# ATSAMA5D27 register map
Vendor: Microchip Technology Inc.; File version: 1.0
CPU: CA5 r0p1, little endian, no MPU, no FPU, 4 interrupt priority bits
Address unit: 32 bits
Registers are 32-bit, read-write, reset 0x0 unless marked. A register's access mark holds for its fields unless they carry their own. Offsets are from the block's base; [hi:lo] are bit positions; {n}, {i} and the like mark numbered series; 'fields as' and 'values as' point back to an identical list.

## PWM — Pulse Width Modulation Controller
Base 0xF802C000
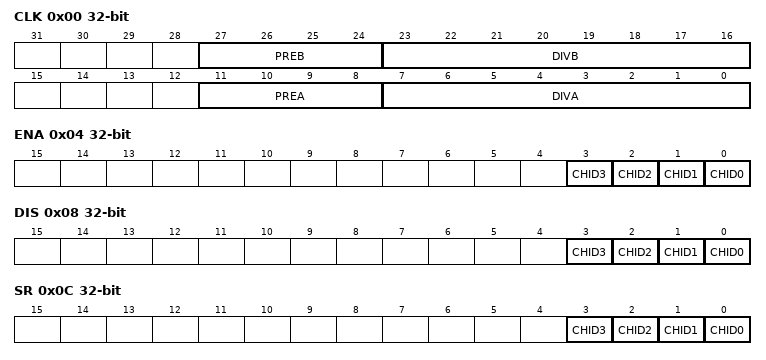
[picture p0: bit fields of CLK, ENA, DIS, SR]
0x00 CLK — PWM Clock Register
  [27:24] PREB — CLKB Source Clock Selection
    0=CLK (Peripheral clock); 1=CLK_DIV2 (Peripheral clock/2); 2=CLK_DIV4 (Peripheral clock/4); 3=CLK_DIV8 (Peripheral clock/8); 4=CLK_DIV16 (Peripheral clock/16); 5=CLK_DIV32 (Peripheral clock/32); 6=CLK_DIV64 (Peripheral clock/64); 7=CLK_DIV128 (Peripheral clock/128); 8=CLK_DIV256 (Peripheral clock/256); 9=CLK_DIV512 (Peripheral clock/512); 10=CLK_DIV1024 (Peripheral clock/1024)
  [23:16] DIVB — CLKB Divide Factor
    0=CLKB_POFF (CLKB clock is turned off); 1=PREB (CLKB clock is clock selected by PREB)
  [11:8] PREA — CLKA Source Clock Selection
    values as PREB
  [7:0] DIVA — CLKA Divide Factor
    0=CLKA_POFF (CLKA clock is turned off); 1=PREA (CLKA clock is clock selected by PREA)
0x04 ENA wo — PWM Enable Register
  [n] CHID{n} rw (n=0..3) — Channel ID
0x08 DIS wo — PWM Disable Register
  [n] CHID{n} rw (n=0..3) — Channel ID
0x0C SR ro — PWM Status Register
  [n] CHID{n} rw (n=0..3) — Channel ID
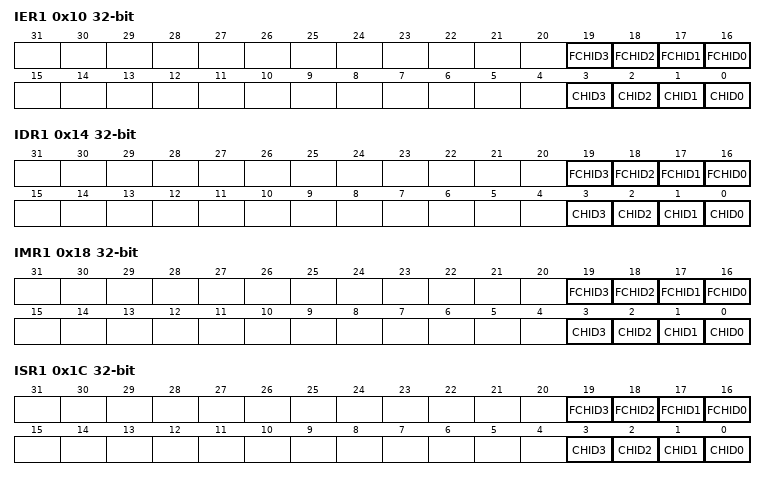
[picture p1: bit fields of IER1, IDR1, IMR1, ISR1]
0x10 IER1 wo — PWM Interrupt Enable Register 1
  [n+16] FCHID{n} rw (n=0..3) — Fault Protection Trigger on Channel {n} Interrupt Enable
  [n] CHID{n} rw (n=0..3) — Counter Event on Channel {n} Interrupt Enable
0x14 IDR1 wo — PWM Interrupt Disable Register 1
  [n+16] FCHID{n} rw (n=0..3) — Fault Protection Trigger on Channel {n} Interrupt Disable
  [n] CHID{n} rw (n=0..3) — Counter Event on Channel {n} Interrupt Disable
0x18 IMR1 ro — PWM Interrupt Mask Register 1
  [n+16] FCHID{n} rw (n=0..3) — Fault Protection Trigger on Channel {n} Interrupt Mask
  [n] CHID{n} rw (n=0..3) — Counter Event on Channel {n} Interrupt Mask
0x1C ISR1 ro — PWM Interrupt Status Register 1
  [n+16] FCHID{n} rw (n=0..3) — Fault Protection Trigger on Channel {n}
  [n] CHID{n} rw (n=0..3) — Counter Event on Channel {n}
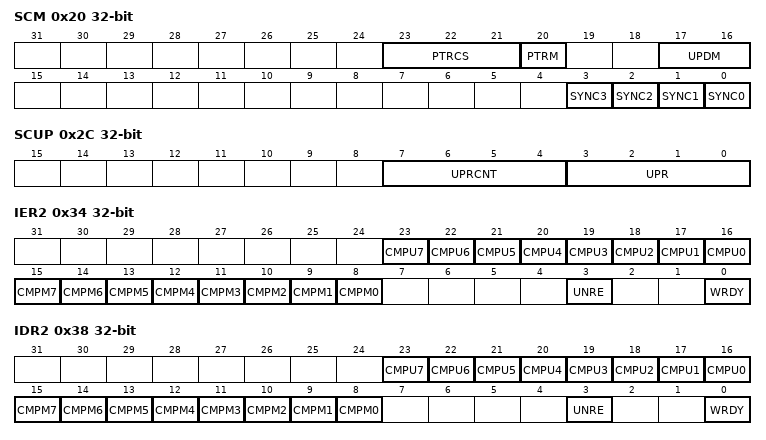
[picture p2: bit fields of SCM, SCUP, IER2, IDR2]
0x20 SCM — PWM Sync Channels Mode Register
  [23:21] PTRCS — DMA Controller Transfer Request Comparison Selection
  [20] PTRM — DMA Controller Transfer Request Mode
  [17:16] UPDM — Synchronous Channels Update Mode
    0=MODE0 (Manual write of double buffer registers and manual update of synchronous channels); 1=MODE1 (Manual write of double buffer registers and automatic update of synchronous channels); 2=MODE2 (Automatic write of duty-cycle update registers by the DMA Controller and automatic update of synchronous channels)
  [n] SYNC{n} (n=0..3) — Synchronous Channel {n}
0x24 DMAR wo — PWM DMA Register
  [23:0] DMADUTY rw — Duty-Cycle Holding Register for DMA Access
0x28 SCUC — PWM Sync Channels Update Control Register
  [0] UPDULOCK — Synchronous Channels Update Unlock
0x2C SCUP — PWM Sync Channels Update Period Register
  [7:4] UPRCNT — Update Period Counter
  [3:0] UPR — Update Period
0x30 SCUPUPD wo — PWM Sync Channels Update Period Update Register
  [3:0] UPRUPD rw — Update Period Update
0x34 IER2 wo — PWM Interrupt Enable Register 2
  [n+16] CMPU{n} rw (n=0..7) — Comparison {n} Update Interrupt Enable
  [n+8] CMPM{n} rw (n=0..7) — Comparison {n} Match Interrupt Enable
  [3] UNRE rw — Synchronous Channels Update Underrun Error Interrupt Enable
  [0] WRDY rw — Write Ready for Synchronous Channels Update Interrupt Enable
0x38 IDR2 wo — PWM Interrupt Disable Register 2
  [n+16] CMPU{n} rw (n=0..7) — Comparison {n} Update Interrupt Disable
  [n+8] CMPM{n} rw (n=0..7) — Comparison {n} Match Interrupt Disable
  [3] UNRE rw — Synchronous Channels Update Underrun Error Interrupt Disable
  [0] WRDY rw — Write Ready for Synchronous Channels Update Interrupt Disable
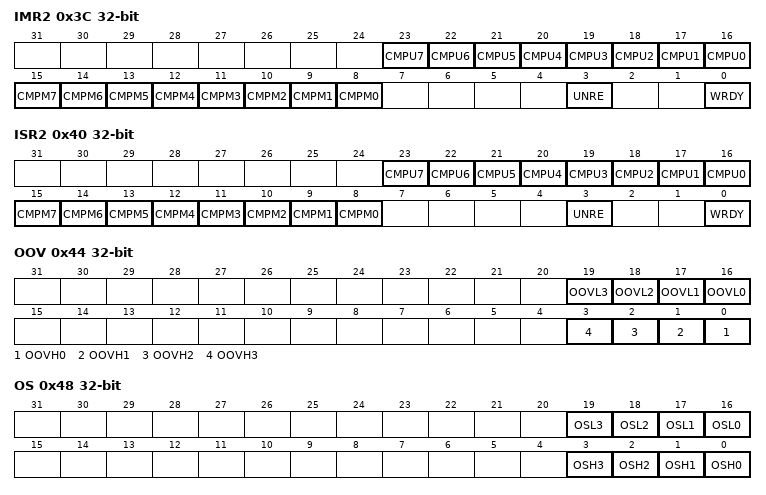
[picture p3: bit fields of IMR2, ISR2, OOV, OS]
0x3C IMR2 ro — PWM Interrupt Mask Register 2
  [n+16] CMPU{n} rw (n=0..7) — Comparison {n} Update Interrupt Mask
  [n+8] CMPM{n} rw (n=0..7) — Comparison {n} Match Interrupt Mask
  [3] UNRE rw — Synchronous Channels Update Underrun Error Interrupt Mask
  [0] WRDY rw — Write Ready for Synchronous Channels Update Interrupt Mask
0x40 ISR2 ro — PWM Interrupt Status Register 2
  [n+16] CMPU{n} rw (n=0..7) — Comparison {n} Update
  [n+8] CMPM{n} rw (n=0..7) — Comparison {n} Match
  [3] UNRE rw — Synchronous Channels Update Underrun Error
  [0] WRDY rw — Write Ready for Synchronous Channels Update
0x44 OOV — PWM Output Override Value Register
  [n+16] OOVL{n} (n=0..3) — Output Override Value for PWML output of the channel {n}
  [n] OOVH{n} (n=0..3) — Output Override Value for PWMH output of the channel {n}
0x48 OS — PWM Output Selection Register
  [n+16] OSL{n} (n=0..3) — Output Selection for PWML output of the channel {n}
  [n] OSH{n} (n=0..3) — Output Selection for PWMH output of the channel {n}
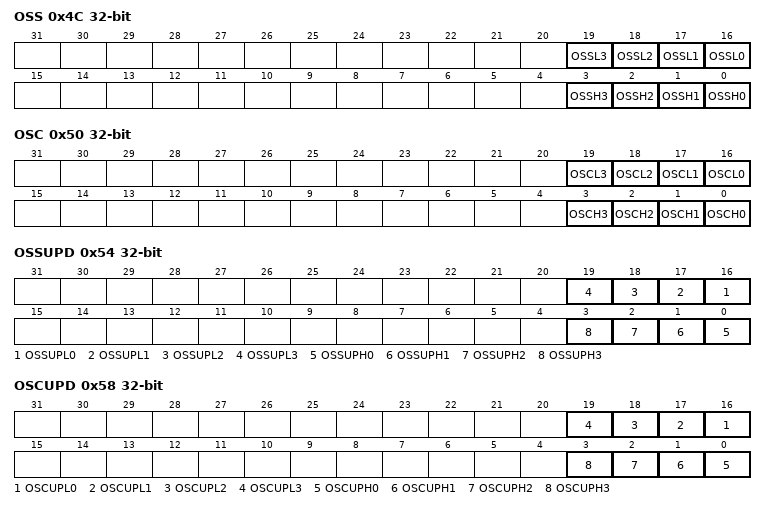
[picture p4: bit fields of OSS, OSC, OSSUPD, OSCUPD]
0x4C OSS wo — PWM Output Selection Set Register
  [n+16] OSSL{n} rw (n=0..3) — Output Selection Set for PWML output of the channel {n}
  [n] OSSH{n} rw (n=0..3) — Output Selection Set for PWMH output of the channel {n}
0x50 OSC wo — PWM Output Selection Clear Register
  [n+16] OSCL{n} rw (n=0..3) — Output Selection Clear for PWML output of the channel {n}
  [n] OSCH{n} rw (n=0..3) — Output Selection Clear for PWMH output of the channel {n}
0x54 OSSUPD wo — PWM Output Selection Set Update Register
  [n+16] OSSUPL{n} rw (n=0..3) — Output Selection Set for PWML output of the channel {n}
  [n] OSSUPH{n} rw (n=0..3) — Output Selection Set for PWMH output of the channel {n}
0x58 OSCUPD wo — PWM Output Selection Clear Update Register
  [n+16] OSCUPL{n} rw (n=0..3) — Output Selection Clear for PWML output of the channel {n}
  [n] OSCUPH{n} rw (n=0..3) — Output Selection Clear for PWMH output of the channel {n}
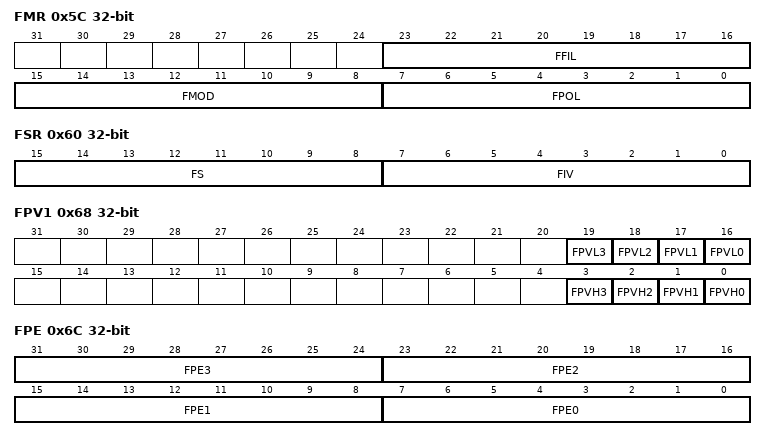
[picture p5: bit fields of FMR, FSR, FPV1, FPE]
0x5C FMR — PWM Fault Mode Register
  [23:16] FFIL — Fault Filtering
  [15:8] FMOD — Fault Activation Mode
  [7:0] FPOL — Fault Polarity
0x60 FSR ro — PWM Fault Status Register
  [15:8] FS rw — Fault Status
  [7:0] FIV rw — Fault Input Value
0x64 FCR wo — PWM Fault Clear Register
  [7:0] FCLR rw — Fault Clear
0x68 FPV1 — PWM Fault Protection Value Register 1
  [n+16] FPVL{n} (n=0..3) — Fault Protection Value for PWML output on channel {n}
  [n] FPVH{n} (n=0..3) — Fault Protection Value for PWMH output on channel {n}
0x6C FPE — PWM Fault Protection Enable Register
  [8n+7:8n] FPE{n} (n=0..3) — Fault Protection Enable for channel {n}
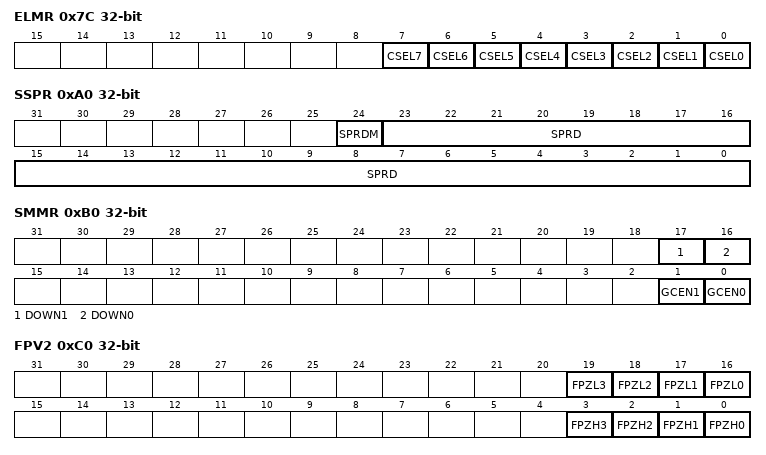
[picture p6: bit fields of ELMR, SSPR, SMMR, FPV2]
0x7C ELMR — PWM Event Line 0 Mode Register
  [n] CSEL{n} (n=0..7) — Comparison {n} Selection
0xA0 SSPR — PWM Spread Spectrum Register
  [24] SPRDM — Spread Spectrum Counter Mode
  [23:0] SPRD — Spread Spectrum Limit Value
0xA4 SSPUP wo — PWM Spread Spectrum Update Register
  [23:0] SPRDUP rw — Spread Spectrum Limit Value Update
0xB0 SMMR — PWM Stepper Motor Mode Register
  [17] DOWN1 — Down Count
  [16] DOWN0 — Down Count
  [1] GCEN1 — Gray Count Enable
  [0] GCEN0 — Gray Count Enable
0xC0 FPV2 — PWM Fault Protection Value 2 Register
  [n+16] FPZL{n} (n=0..3) — Fault Protection to Hi-Z for PWML output on channel {n}
  [n] FPZH{n} (n=0..3) — Fault Protection to Hi-Z for PWMH output on channel {n}
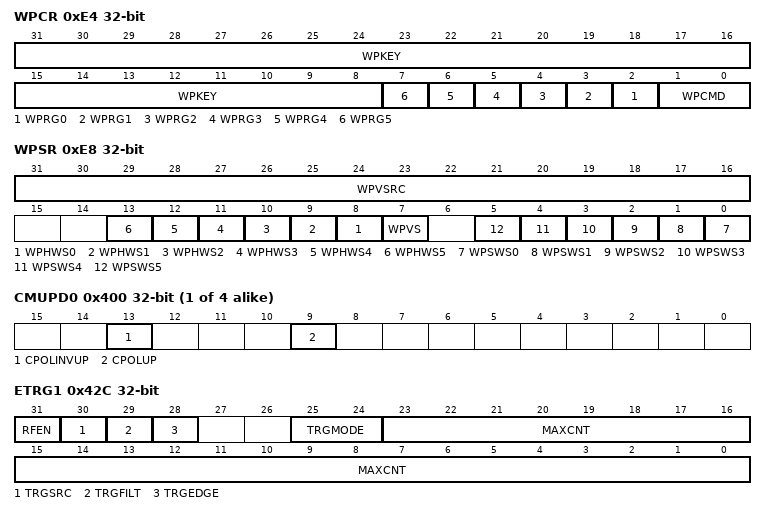
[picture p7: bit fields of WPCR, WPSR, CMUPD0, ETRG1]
0xE4 WPCR wo — PWM Write Protection Control Register
  [31:8] WPKEY rw — Write Protection Key
    0x50574D=PASSWD (Writing any other value in this field aborts the write operation of the WPCMD field.Always reads as 0)
  [n+2] WPRG{n} rw (n=0..5) — Write Protection Register Group {n}
  [1:0] WPCMD rw — Write Protection Command
    0=DISABLE_SW_PROT (Disables the software write protection of the register groups of which the bit WPRGx is at '1'.); 1=ENABLE_SW_PROT (Enables the software write protection of the register groups of which the bit WPRGx is at '1'.); 2=ENABLE_HW_PROT (Enables the hardware write protection of the register groups of which the bit WPRGx is at '1'. Only a hardware reset of the PWM controller can disable the hardware write protection. Moreover, to meet security requirements, the PIO lines associated with the PWM can not be configured through the PIO interface.)
0xE8 WPSR ro — PWM Write Protection Status Register
  [31:16] WPVSRC rw — Write Protect Violation Source
  [n+8] WPHWS{n} rw (n=0..5) — Write Protect HW Status
  [7] WPVS rw — Write Protect Violation Status
  [n] WPSWS{n} rw (n=0..5) — Write Protect SW Status
{0x400+0x20*i} CMUPD{i} wo (i=0..3) — PWM Channel Mode Update Register (ch_num = {i})
  [13] CPOLINVUP rw — Channel Polarity Inversion Update
  [9] CPOLUP rw — Channel Polarity Update
0x42C ETRG1 — PWM External Trigger Register 1
  [31] RFEN — Recoverable Fault Enable
  [30] TRGSRC — Trigger Source
  [29] TRGFILT — Filtered input
  [28] TRGEDGE — Edge Selection
    0=FALLING_ZERO (TRGMODE = 1: TRGINx event detection on falling edge.TRGMODE = 2, 3: TRGINx active level is 0); 1=RISING_ONE (TRGMODE = 1: TRGINx event detection on rising edge.TRGMODE = 2, 3: TRGINx active level is 1)
  [25:24] TRGMODE — External Trigger Mode
    0=OFF (External trigger is not enabled.); 1=MODE1 (External PWM Reset Mode); 2=MODE2 (External PWM Start Mode); 3=MODE3 (Cycle-by-cycle Duty Mode)
  [23:0] MAXCNT — Maximum Counter value
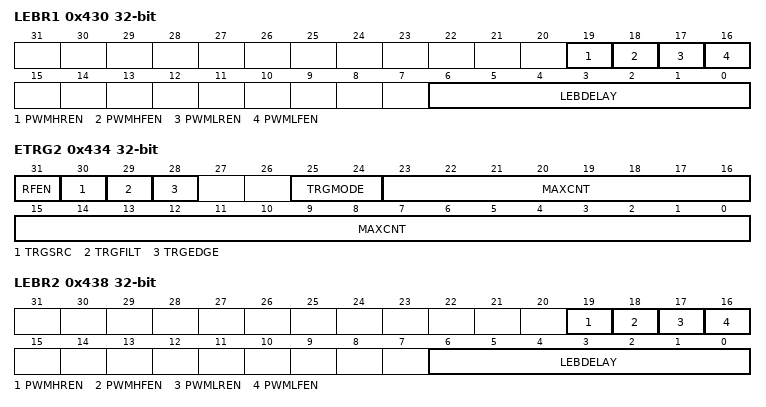
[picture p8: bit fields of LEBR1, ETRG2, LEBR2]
0x430 LEBR1 — PWM Leading-Edge Blanking Register 1
  [19] PWMHREN — PWMH Rising Edge Enable
  [18] PWMHFEN — PWMH Falling Edge Enable
  [17] PWMLREN — PWML Rising Edge Enable
  [16] PWMLFEN — PWML Falling Edge Enable
  [6:0] LEBDELAY — Leading-Edge Blanking Delay for TRGINx
0x434 ETRG2 — PWM External Trigger Register 2
  fields as ETRG1
0x438 LEBR2 — PWM Leading-Edge Blanking Register 2
  fields as LEBR1
